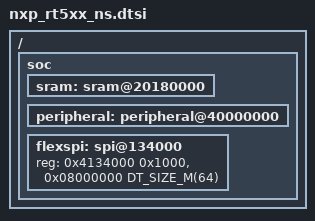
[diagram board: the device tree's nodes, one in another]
/*
 * Copyright (c) 2022, NXP
 *
 * SPDX-License-Identifier: Apache-2.0
 */

#include <mem.h>

/ {
	soc {
		sram: sram@20180000 {
			ranges = <0x20180000 0x20180000 0x300000>;
		};

		peripheral: peripheral@40000000 {
			ranges = <0x0 0x40000000 0x10000000>;
		};

		flexspi: spi@134000 {
			reg = <0x4134000 0x1000>, <0x08000000 DT_SIZE_M(64)>;
		};
	};
};

#include "nxp_rt5xx_common.dtsi"
